# wl_phy_ocp_ic_secure register map
Vendor: Texas Instruments
Peripheral module from a debugger description file (folder CC35X1E).
Registers are 32-bit, access per field, reset values left out (the file's numbers can be read two ways) unless marked. A register's access mark holds for its fields unless they carry their own. Offsets are as the file gives them; lines under a group give offsets from that group; [hi:lo] are bit positions; {n}, {i} and the like mark numbered series; 'fields as' and 'values as' point back to an identical list; <NAME> marks a mode.

## wl_phy_ocp_ic_secure
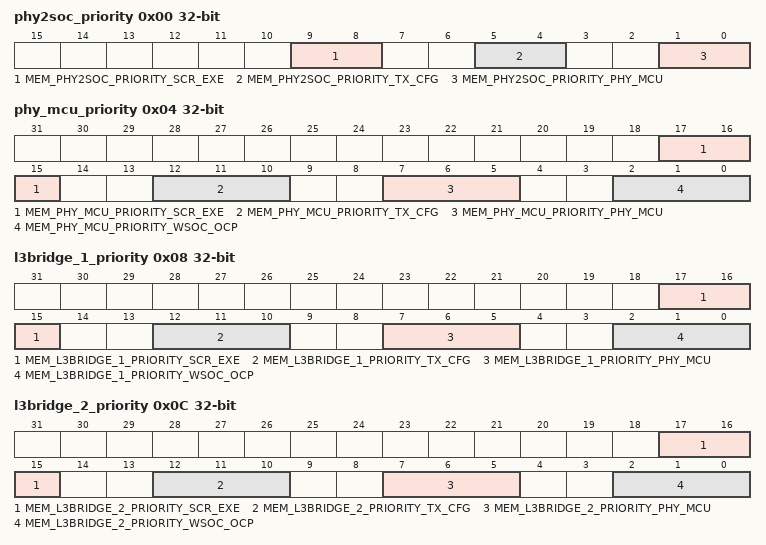
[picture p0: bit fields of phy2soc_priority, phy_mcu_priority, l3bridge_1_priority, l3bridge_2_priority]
0x00 phy2soc_priority — every master has a priority for this slave: 0 - low .. 3 - high
  [9:8] MEM_PHY2SOC_PRIORITY_SCR_EXE rw — low high values: 0 , 1, 2, 3
  [5:4] MEM_PHY2SOC_PRIORITY_TX_CFG rw — low high values: 0 , 1, 2, 3
  [1:0] MEM_PHY2SOC_PRIORITY_PHY_MCU rw — low high values: 0 , 1, 2, 3
0x04 phy_mcu_priority — every master has a priority for this slave: 0 - low .. 3 - high
  [17:15] MEM_PHY_MCU_PRIORITY_SCR_EXE rw — low high values: 0 , 1, 2, 3
  [12:10] MEM_PHY_MCU_PRIORITY_TX_CFG rw — low high values: 0 , 1, 2, 3
  [7:5] MEM_PHY_MCU_PRIORITY_PHY_MCU rw — low high values: 0 , 1, 2, 3
  [2:0] MEM_PHY_MCU_PRIORITY_WSOC_OCP rw — low high values: 0 , 1, 2, 3
0x08 l3bridge_1_priority — every master has a priority for this slave: 0 - low .. 3 - high
  [17:15] MEM_L3BRIDGE_1_PRIORITY_SCR_EXE rw — low high values: 0 , 1, 2, 3
  [12:10] MEM_L3BRIDGE_1_PRIORITY_TX_CFG rw — low high values: 0 , 1, 2, 3
  [7:5] MEM_L3BRIDGE_1_PRIORITY_PHY_MCU rw — low high values: 0 , 1, 2, 3
  [2:0] MEM_L3BRIDGE_1_PRIORITY_WSOC_OCP rw — low high values: 0 , 1, 2, 3
0x0C l3bridge_2_priority — every master has a priority for this slave: 0 - low .. 3 - high
  [17:15] MEM_L3BRIDGE_2_PRIORITY_SCR_EXE rw — low high values: 0 , 1, 2, 3
  [12:10] MEM_L3BRIDGE_2_PRIORITY_TX_CFG rw — low high values: 0 , 1, 2, 3
  [7:5] MEM_L3BRIDGE_2_PRIORITY_PHY_MCU rw — low high values: 0 , 1, 2, 3
  [2:0] MEM_L3BRIDGE_2_PRIORITY_WSOC_OCP rw
0x10 timeout_cfg_slv
  [8:4] MEM_SLV_TIMEOUT_VAL rw — value for timeout for all slaves: valid value - 0x0- 0x1F if value is 0 timeout feature is disabled for all slaves Granulation is double word (64b): 1 - means 16 clocks period, 2 - means 32 clocks period... in h/w the value in FIELD is shifted left 4 times (x16). example: 0x08 => 0x80 (8 means 128)
0x28 ocp_slave_serror_and_timeout_1_status rw
  [31:0] MEM_SERROR_AND_TIMEOUT_STATUS_1_WROPT — status bits when ocp slave response with serror clear on write sticky - catch the first error, until register is cleared to 0 [31:0] - maddr *note - can only clear on write to 32b0 writing 1 byte will clear all 4 bytes
0x2C ocp_slave_serror_and_timeout_2_status
  [9:0] MEM_SERROR_AND_TIMEOUT_STATUS_2_WROPT rw — status bits when ocp slave response with serror or timeout: clear on write sticky - catch the first error, until register is cleared to 0 for serror and timeout handeling: [9:6] cause [5:4] mcmd - command type: 2=RD ; 1=WR [3:0] masterid cause mapping: 0 - masters 1 - phy2soc 2 - phy_mcu 3 - l3bridge_1 4 - l3bridge_2 masterid mapping: 0 - wsoc 1 - phy_mcu 2 - tx_cfg 3 - scr_exe *note - can only clear on write to 10'b0 writing 1 byte will clear all 2 bytes
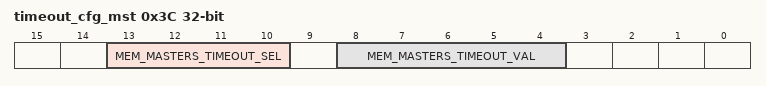
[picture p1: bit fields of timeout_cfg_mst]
0x3C timeout_cfg_mst — by default timout for masters is disabled.
  [13:10] MEM_MASTERS_TIMEOUT_SEL rw — master id [3:0] - 0 - wsoc 1 - phy_mcu 2 - tx_cfg 3 - scr_exe
  [8:4] MEM_MASTERS_TIMEOUT_VAL rw — value for timeout for all slaves: valid value - 0x0- 0x1F if value is 0 timeout feature is disabled for all slaves Granulation is double word (64b): 1 - means 16 clocks period, 2 - means 32 clocks period... in h/w the value in FIELD is shifted left 4 times (x16). example: 0x08 => 0x80 (8 means 128)
